# MCASP0_CFG register map
Vendor: Texas Instruments
Registers are 32-bit, read-write, reset 0x0 unless marked. A register's access mark holds for its fields unless they carry their own. Offsets are as the file gives them; [hi:lo] are bit positions; {n}, {i} and the like mark numbered series.

## MCASP0_CFG (part 2 of 3)
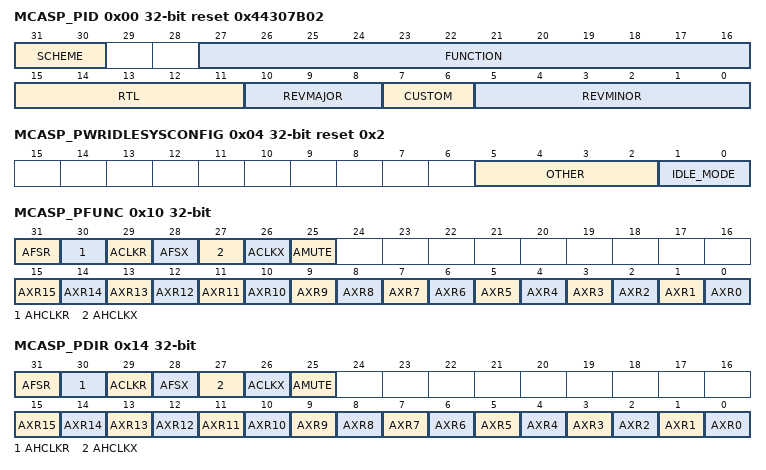
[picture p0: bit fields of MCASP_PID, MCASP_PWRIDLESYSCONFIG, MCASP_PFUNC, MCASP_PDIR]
0x00 MCASP_PID ro reset 0x44307B02
  [31:30] SCHEME — Distinguishes between old scheme and current.
  [27:16] FUNCTION — Indicates a software-compatible module family.
  [15:11] RTL — RTL version.
  [10:8] REVMAJOR — Major revision number.
  [7:6] CUSTOM — Indicates a special version for a given device.
  [5:0] REVMINOR — Minor revision number.
0x04 MCASP_PWRIDLESYSCONFIG access per field reset 0x2 — Power Idle SYSCONFIG register.
  [5:2] OTHER rw — Reserved for future programming.
  [1:0] IDLE_MODE rw — Power management Configuration of the local target state management mode. By definition, target can handle read/write transaction as long as it is out of IDLE state. 0h = Force-idle mode: local target's idle state follows (acknowledges) the system's idle requests unconditionally, i.e. regardless of the IP module's internal requirements. Backup mode, for debug only. 1h = No-idle mode: local target never enters idle state. Backup mode, for debug only. 2h = Smart-idle mode: local target's idle state eventually follows (acknowledges) the system's idle requests, depending on the IP module's internal requirements. IP module shall not generate (IRQor DMA-request-related) wakeup events. 3h = Reserved.
0x10 MCASP_PFUNC access per field
  [31] AFSR rw — Determines if AFSR pin functions as McASP or GPIO.0h = Pin functions as McASP pin. 1h = Pin functions as GPIO pin.
  [30] AHCLKR rw — Determines if AHCLKR pin functions as McASP or GPIO.0h = Pin functions as McASP pin. 1h = Pin functions as GPIO pin.
  [29] ACLKR rw — Determines if ACLKR pin functions as McASP or GPIO.0h = Pin functions as McASP pin. 1h = Pin functions as GPIO pin.
  [28] AFSX rw — Determines if AFSX pin functions as McASP or GPIO.0h = Pin functions as McASP pin. 1h = Pin functions as GPIO pin.
  [27] AHCLKX rw — Determines if AHCLKX pin functions as McASP or GPIO.0h = Pin functions as McASP pin. 1h = Pin functions as GPIO pin.
  [26] ACLKX rw — Determines if ACLKX pin functions as McASP or GPIO.0h = Pin functions as McASP pin. 1h = Pin functions as GPIO pin.
  [25] AMUTE rw — Determines if AMUTE pin functions as McASP or GPIO.0h = Pin functions as McASP pin. 1h = Pin functions as GPIO pin.
  [n] AXR{n} rw (n=0..15) — Determines if AXR{n} pin functions as McASP or GPIO.0h = Pin functions as McASP pin. 1h = Pin functions as GPIO pin.
0x14 MCASP_PDIR access per field
  [31] AFSR rw — Determines if AFSR pin functions as an input or output.0h = Pin functions as input. 1h = Pin functions as output.
  [30] AHCLKR rw — Determines if AHCLKR pin functions as an input or output.0h = Pin functions as input. 1h = Pin functions as output.
  [29] ACLKR rw — Determines if ACLKR pin functions as an input or output.0h = Pin functions as input. 1h = Pin functions as output.
  [28] AFSX rw — Determines if AFSX pin functions as an input or output.0h = Pin functions as input. 1h = Pin functions as output.
  [27] AHCLKX rw — Determines if AHCLKX pin functions as an input or output.0h = Pin functions as input. 1h = Pin functions as output.
  [26] ACLKX rw — Determines if ACLKX pin functions as an input or output.0h = Pin functions as input. 1h = Pin functions as output.
  [25] AMUTE rw — Determines if AMUTE pin functions as an input or output.0h = Pin functions as input. 1h = Pin functions as output.
  [n] AXR{n} rw (n=0..15) — Determines if AXR{n} pin functions as an input or output.0h = Pin functions as input. 1h = Pin functions as output.
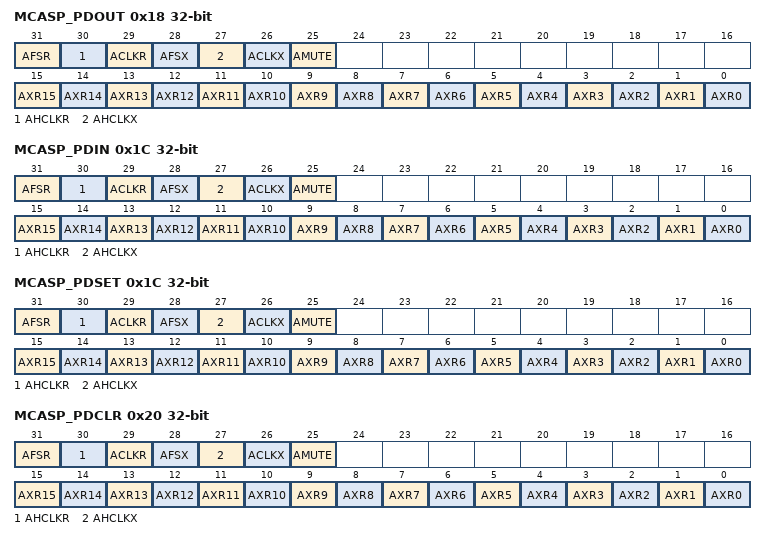
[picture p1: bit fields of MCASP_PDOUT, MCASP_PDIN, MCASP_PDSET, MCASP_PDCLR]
0x18 MCASP_PDOUT access per field
  [31] AFSR rw — Determines drive on AFSR output pin when the correspondingMCASP_PFUNC[31] and MCASP_PDIR[31] bits are set to 1. 0h = Pin drives low. 1h = Pin drives high.
  [30] AHCLKR rw — Determines drive on AHCLKR output pin when the correspondingMCASP_PFUNC[30] and MCASP_PDIR[30] bits are set to 1. 0h = Pin drives low. 1h = Pin drives high.
  [29] ACLKR rw — Determines drive on ACLKR output pin when the correspondingMCASP_PFUNC[29] and MCASP_PDIR[29] bits are set to 1. 0h = Pin drives low. 1h = Pin drives high.
  [28] AFSX rw — Determines drive on AFSX output pin when the correspondingMCASP_PFUNC[28] and MCASP_PDIR[28] bits are set to 1. 0h = Pin drives low. 1h = Pin drives high.
  [27] AHCLKX rw — Determines drive on AHCLKX output pin when the correspondingMCASP_PFUNC[27] and MCASP_PDIR[27] bits are set to 1. 0h = Pin drives low. 1h = Pin drives high.
  [26] ACLKX rw — Determines drive on ACLKX output pin when the correspondingMCASP_PFUNC[26] and MCASP_PDIR[26] bits are set to 1. 0h = Pin drives low. 1h = Pin drives high.
  [25] AMUTE rw — Determines drive on AMUTE output pin when the correspondingMCASP_PFUNC[25] and MCASP_PDIR[25] bits are set to 1. 0h = Pin drives low. 1h = Pin drives high.
  [n] AXR{n} rw (n=0..15) — Determines drive on AXR{n} output pin when the correspondingMCASP_PFUNC[{n}] and MCASP_PDIR[{n}] bits are set to 1. 0h = Pin drives low. 1h = Pin drives high.
0x1C MCASP_PDIN ro — The pin data input register (PDIN) holds the I/O pin state of each of the McASP pins. PDIN allows the actual value of the pin to be read, regardless of the state of PFUNC and PDIR.
  [31] AFSR — Logic level on AFSR pin.0h = Pin is logic low. 1h = Pin is logic high.
  [30] AHCLKR — Logic level on AHCLKR pin.0h = Pin is logic low. 1h = Pin is logic high.
  [29] ACLKR — Logic level on ACLKR pin.0h = Pin is logic low. 1h = Pin is logic high.
  [28] AFSX — Logic level on AFSX pin.0h = Pin is logic low. 1h = Pin is logic high.
  [27] AHCLKX — Logic level on AHCLKX pin.0h = Pin is logic low. 1h = Pin is logic high.
  [26] ACLKX — Logic level on ACLKX pin.0h = Pin is logic low. 1h = Pin is logic high.
  [25] AMUTE — Logic level on AMUTE pin.0h = Pin is logic low. 1h = Pin is logic high.
  [n] AXR{n} (n=0..15) — Logic level on AXR{n} pin.0h = Pin is logic low. 1h = Pin is logic high.
0x1C MCASP_PDSET access per field — The pin data set register (PDSET) is an alias of the pin data output register (PDOUT) for writes only. Writing a 1 to the PDSET bit sets the corresponding bit in PDOUT and, if PFUNC = 1 (GPIO function) and PDIR = 1 (output), drives a logic high on the pin.
  [31] AFSR wo — Allows the corresponding AFSR bit inMCASP_PDOUT to be set to a logic high without affecting other I/O pins controlled by the same port. 0h = No effect. 1h =
  [30] AHCLKR wo — Allows the corresponding AHCLKR bit inMCASP_PDOUT to be set to a logic high without affecting other I/O pins controlled by the same port. 0h = No effect. 1h =
  [29] ACLKR wo — Allows the corresponding ACLKR bit inMCASP_PDOUT to be set to a logic high without affecting other I/O pins controlled by the same port. 0h = No effect. 1h =
  [28] AFSX wo — Allows the corresponding AFSX bit inMCASP_PDOUT to be set to a logic high without affecting other I/O pins controlled by the same port. 0h = No effect. 1h =
  [27] AHCLKX wo — Allows the corresponding AHCLKX bit inMCASP_PDOUT to be set to a logic high without affecting other I/O pins controlled by the same port. 0h = No effect. 1h =
  [26] ACLKX wo — Allows the corresponding ACLKX bit inMCASP_PDOUT to be set to a logic high without affecting other I/O pins controlled by the same port. 0h = No effect. 1h =
  [25] AMUTE wo — Allows the corresponding AMUTE bit inMCASP_PDOUT to be set to a logic high without affecting other I/O pins controlled by the same port. 0h = No effect. 1h =
  [n] AXR{n} wo (n=0..15) — Allows the corresponding AXR{n} bit inMCASP_PDOUT to be set to a logic high without affecting other I/O pins controlled by the same port. 0h = No effect. 1h =
0x20 MCASP_PDCLR access per field — The pin data clear register (PDCLR) is an alias of the pin data output register (PDOUT) for writes only. Writing a 1 to the PDCLR bit clears the corresponding bit in PDOUT and, if PFUNC = 1 (GPIO function) and PDIR = 1 (output), drives a logic low on the pin.
  [31] AFSR rw — Allows the corresponding AFSR bit inMCASP_PDOUT to be cleared to a logic low without affecting other I/O pins controlled by the same port. 0h = No effect. 1h =
  [30] AHCLKR rw — Allows the corresponding AHCLKR bit inMCASP_PDOUT to be cleared to a logic low without affecting other I/O pins controlled by the same port. 0h = No effect. 1h =
  [29] ACLKR rw — Allows the corresponding ACLKR bit inMCASP_PDOUT to be cleared to a logic low without affecting other I/O pins controlled by the same port. 0h = No effect. 1h =
  [28] AFSX rw — Allows the corresponding AFSX bit inMCASP_PDOUT to be cleared to a logic low without affecting other I/O pins controlled by the same port. 0h = No effect. 1h =
  [27] AHCLKX rw — Allows the corresponding AHCLKX bit inMCASP_PDOUT to be cleared to a logic low without affecting other I/O pins controlled by the same port. 0h = No effect. 1h =
  [26] ACLKX rw — Allows the corresponding ACLKX bit inMCASP_PDOUT to be cleared to a logic low without affecting other I/O pins controlled by the same port. 0h = No effect. 1h =
  [25] AMUTE rw — Allows the corresponding AMUTE bit inMCASP_PDOUT to be cleared to a logic low without affecting other I/O pins controlled by the same port. 0h = No effect. 1h =
  [n] AXR{n} rw (n=0..15) — Allows the corresponding AXR[{n}] bit inMCASP_PDOUT to be cleared to a logic low without affecting other I/O pins controlled by the same port. 0h = No effect. 1h =
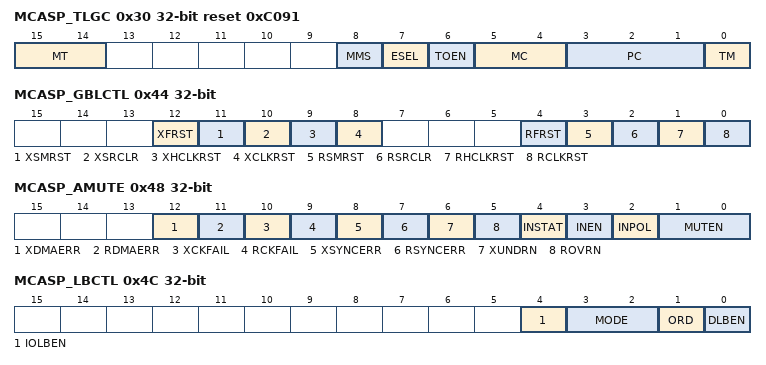
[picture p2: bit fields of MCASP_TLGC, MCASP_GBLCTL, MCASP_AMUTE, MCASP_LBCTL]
0x30 MCASP_TLGC access per field reset 0xC091 — for IODFT
  [15:14] MT rw — MISR on/off trigger command. These monitor trigger codes only are affective for the MISR signature capture when MC = 3h. MT Code effect on MISR: 0h = MISR capture start on the first active cycle decode of the IP bus activity and continues to update the signature for every active cycle. 1h = MISR capture start on the first active cycle decode of IP bus activity and continues to update the signature until the Execution Counter expires (TLEC). 2h = inactive/no effect 3h = inactive/no effect (default)
  [8] MMS rw — Chooses the source of the MISR input: 0h = output register 1h = input capture
  [7] ESEL rw — Output enable select: 0h = test mode, and the functional OEN is gated off 1h = normal functional mode
  [6] TOEN rw — Test output enable control. This signal is paired with ESEL. TOEN is never 1 when ESEL is 1. When ESEL is 0 (test mode), TOEN is: 0h = output enabled 1h = output disabled Note: In boundary scan mode this signal is not selected, and the BSR controls output enables.
  [5:4] MC rw — This defines the states of the MISR: 0h = download results 1h = hold current value 2h = load initial value (from PC bits) 3h = MISR enable to capture signature
  [3:1] PC rw — Pattern code defines the type of pattern that is selected for the artificial pattern generation logic in the IODFT. Modes: 0h = functional (default) 1h = random XOR 2h = random XNOR 3h = shift register 4h = hold current value Note: McASP does not have an input pattern generator (PG).
  [0] TM rw — At reset the value is 1 for normal functional mode. This bit is tied high, and should not be written to.
0x34 MCASP_TLMR — for IODFT
  [31:0] TLMR — This contains the result signature of a given test after the download function is executed.
0x38 MCASP_TLEC — for IODFT
  [31:0] TLEC — Contains the number of cycles during which the MISR signature will be accumulated.
0x44 MCASP_GBLCTL access per field
  [12] XFRST rw — Transmit frame sync generator reset enable bit.0h = Transmit frame sync generator is reset. 1h = Transmit frame sync generator is active. When released from reset, the transmit frame sync generator begins counting serial clocks and generating frame sync as programmed.
  [11] XSMRST rw — Transmit state machine reset enable bit.0h = Transmit state machine is held in reset. AXRn pin state: If 1h = Transmit state machine is released from reset. When released from reset, the transmit state machine immediately transfers data from XRBUF[n] to XRSR[n]. The transmit state machine sets the underrun flag (XUNDRN) in MCASP_XSTAT, if XRBUF[n] have not been preloaded with data before reset is released. The transmit state machine also immediately begins detecting frame sync and is ready to transmit. Transmit TDM time slot begins at slot 0 after reset is released.
  [10] XSRCLR rw — Transmit serializer clear enable bit. By clearing then setting this bit, the transmit buffer is flushed to an empty state [XDATA = 1]. If XSMRST = 1, XSRCLR = 1, XDATA = 1, and XBUF is not loaded with new data before the start of the next active time slot, an underrun will occur. 0h = Transmit serializers are cleared. 1h = Transmit serializers are active. When the transmit serializers are first taken out of reset (XSRCLR changes from 0 to 1), the transmit data ready bit (XDATA) in MCASP_XSTAT is set to indicate XBUF is ready to be written.
  [9] XHCLKRST rw — Transmit high-frequency clock divider reset enable bit.0h = Transmit high-frequency clock divider is held in reset and passes through its input as divide-by-1. 1h = Transmit high-frequency clock divider is running.
  [8] XCLKRST rw — Transmit clock divider reset enable bit.0h = Transmit clock divider is held in reset. When the clock divider is in reset, it passes through a divide-by-1 of its input. 1h = Transmit clock divider is running.
  [4] RFRST rw — Receive frame sync generator reset enable bit.0h = Receive frame sync generator is reset. 1h = Receive frame sync generator is active. When released from reset, the receive frame sync generator begins counting serial clocks and generating frame sync as programmed.
  [3] RSMRST rw — Receive state machine reset enable bit.0h = Receive state machine is held in reset. 1h = Receive state machine is released from reset. When released from reset, the receive state machine immediately begins detecting frame sync and is ready to receive. Receive TDM time slot begins at slot 0 after reset is released.
  [2] RSRCLR rw — Receive serializer clear enable bit. By clearing then setting this bit, the receive buffer is flushed. 0h = Receive serializers are cleared. 1h = Receive serializers are active.
  [1] RHCLKRST rw — Receive high-frequency clock divider reset enable bit.0h = Receive high-frequency clock divider is held in reset and passes through its input as divide-by-1. 1h = Receive high-frequency clock divider is running.
  [0] RCLKRST rw — Receive high-frequency clock divider reset enable bit.0h = Receive clock divider is held in reset. When the clock divider is in reset, it passes through a divide-by-1 of its input. 1h = Receive clock divider is running.
0x48 MCASP_AMUTE access per field
  [12] XDMAERR rw — If transmit DMA error [XDMAERR], driveMCASP_AMUTE active enable bit. 0h = Drive is disabled. Detection of transmit DMA error is ignored by 1h = Drive is enabled (active). Upon detection of transmit DMA error,
  [11] RDMAERR rw — If receive DMA error [RDMAERR], driveMCASP_AMUTE active enable bit. 0h = Drive is disabled. Detection of receive DMA error is ignored by 1h = Drive is enabled (active). Upon detection of receive DMA error,
  [10] XCKFAIL rw — If transmit clock failure [XCKFAIL], driveMCASP_AMUTE active enable bit. 0h = Drive is disabled. Detection of transmit clock failure is ignored by 1h = Drive is enabled (active). Upon detection of transmit clock failure,
  [9] RCKFAIL rw — If receive clock failure [RCKFAIL], driveMCASP_AMUTE active enable bit. 0h = Drive is disabled. Detection of receive clock failure is ignored by 1h = Drive is enabled (active). Upon detection of receive clock failure,
  [8] XSYNCERR rw — If unexpected transmit frame sync error [XSYNCERR], driveMCASP_AMUTE active enable bit. 0h = Drive is disabled. Detection of unexpected transmit frame sync error is ignored by 1h = Drive is enabled (active). Upon detection of unexpected transmit frame sync error,
  [7] RSYNCERR rw — If unexpected receive frame sync error [RSYNCERR], driveMCASP_AMUTE active enable bit. 0h = Drive is disabled. Detection of unexpected receive frame sync error is ignored by 1h = Drive is enabled (active). Upon detection of unexpected receive frame sync error,
  [6] XUNDRN rw — If transmit underrun error [XUNDRN], driveMCASP_AMUTE active enable bit. 0h = Drive is disabled. Detection of transmit underrun error is ignored by 1h = Drive is enabled (active). Upon detection of transmit underrun error,
  [5] ROVRN rw — If receiver overrun error [ROVRN], driveMCASP_AMUTE active enable bit. 0h = Drive is disabled. Detection of receiver overrun error is ignored by 1h = Drive is enabled (active). Upon detection of receiver overrun error,
  [4] INSTAT ro — Determines drive on AXRn pin whenMCASP_PFUNC[n] and MCASP_PDIR[n] bits are set to 1. 0h = AMUTEIN pin is inactive. 1h = AMUTEIN pin is active. Audio mute in error is detected.
  [3] INEN rw — DriveMCASP_AMUTE active when AMUTEIN error is active [INSTAT = 1]. 0h = Drive is disabled. AMUTEIN is ignored by 1h = Drive is enabled (active). INSTAT = 1 drives
  [2] INPOL rw — Audio mute in [AMUTEIN] polarity select bit.0h = Polarity is active high. A high on AMUTEIN sets INSTAT to 1. 1h = Polarity is active low. A low on AM UTEIN sets INSTAT to 1.
  [1:0] MUTEN rw — MCASP_AMUTE pin enable bit [unless overridden by GPIO registers]. 0h = 1h = 2h = 3h = Reserved
0x4C MCASP_LBCTL
  [4] IOLBEN — I/O loopback enable. Chip-level loopback; looped back through I/O buffers. 0h = I/O loopback disabled 1h = I/O loopback enabled Note: These are only valid if LBEN = 1. If LBEN = 0, neither internal nor I/O loopback will be selected.
  [3:2] MODE — Loopback generator mode bits. Applies only when loopback mode is enabled [DLBEN = 1]. 0h = Default and reserved on loopback mode (DLBEN = 1). When in non-loopback mode (DLBEN = 0), MODE should be left at default (00). When in loopback mode (DLBEN = 1), MODE = 00 is reserved and is not applicable. 1h = Transmit clock and frame sync generators used by both transmit and receive sections. When in loopback mode (DLBEN = 1), MODE must be 01. 2h = Reserved. 3h = Reserved.
  [1] ORD — Loopback order bit when loopback mode is enabled [DLBEN = 1].0h = Odd serializers N + 1 transmit to even serializers N that receive. The corresponding serializers must be programmed properly. 1h = Even serializers N transmit to odd serializers N + 1 that receive. The corresponding serializers must be programmed properly.
  [0] DLBEN — Loopback mode enable bit.0h = Loopback mode is disabled. 1h = Loopback mode is enabled.
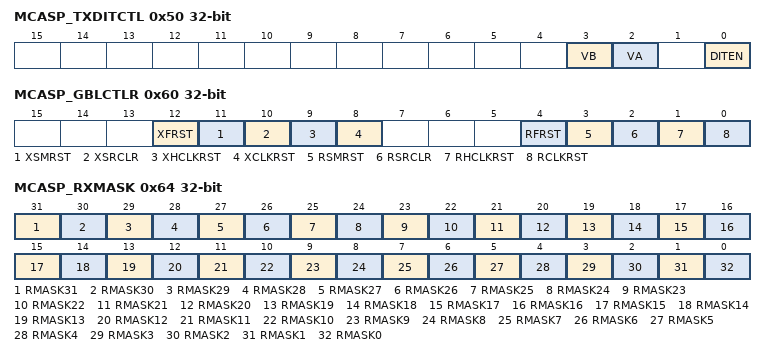
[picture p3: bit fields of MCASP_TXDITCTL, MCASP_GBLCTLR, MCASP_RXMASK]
0x50 MCASP_TXDITCTL
  [3] VB — Valid bit for odd time slots [DIT right subframe].0h = V bit is 0 during odd DIT subframes. 1h = V bit is 1 during odd DIT subframes.
  [2] VA — Valid bit for even time slots [DIT left subframe].0h = V bit is 0 during even DIT subframes. 1h = V bit is 1 during even DIT subframes.
  [0] DITEN — DIT mode enable bit. DITEN should only be changed while the XSMRST bit in MCASP_GBLCTL is in reset [and for startup, XSRCLR also in reset]. However, it is not necessary to reset the XCLKRST or XHCLKRST bits in MCASP_GBLCTL to change DITEN. 0h = DIT mode is disabled. Transmitter operates in TDM or burst mode. 1h = DIT mode is enabled. Transmitter operates in DIT encoded mode.
0x60 MCASP_GBLCTLR access per field
  [12] XFRST ro — Transmit frame sync generator reset enable bit. A read of this bit returns the XFRST bit value of MCASP_GBLCTL. Writes have no effect.
  [11] XSMRST ro — Transmit state machine reset enable bit. A read of this bit returns the XSMRST bit value of MCASP_GBLCTL. Writes have no effect.
  [10] XSRCLR ro — Transmit serializer clear enable bit. A read of this bit returns the XSRCLR bit value of MCASP_GBLCTL. Writes have no effect.
  [9] XHCLKRST ro — Transmit high-frequency clock divider reset enable bit. A read of this bit returns the XHCLKRST bit value of MCASP_GBLCTL. Writes have no effect.
  [8] XCLKRST ro — Transmit clock divider reset enable bit. A read of this bit returns the XCLKRST bit value of MCASP_GBLCTL. Writes have no effect.
  [4] RFRST rw — Receive frame sync generator reset enable bit. A write to this bit affects the RFRST bit of MCASP_GBLCTL. 0h = Receive frame sync generator is reset. 1h = Receive frame sync generator is active.
  [3] RSMRST rw — Receive state machine reset enable bit. A write to this bit affects the RSMRST bit of MCASP_GBLCTL. 0h = Receive state machine is held in reset. 1h = Receive state machine is released from reset.
  [2] RSRCLR rw — Receive serializer clear enable bit. A write to this bit affects the RSRCLR bit of MCASP_GBLCTL. 0h = Receive serializers are cleared. 1h = Receive serializers are active.
  [1] RHCLKRST rw — Receive high-frequency clock divider reset enable bit. A write to this bit affects the RHCLKRST bit of MCASP_GBLCTL. 0h = Receive high-frequency clock divider is held in reset and passes through its input as divide-by-1. 1h = Receive high-frequency clock divider is running.
  [0] RCLKRST rw — Receive clock divider reset enable bit. A write to this bit affects the RCLKRST bit of MCASP_GBLCTL. 0h = Receive clock divider is held in reset. 1h = Receive clock divider is running.
0x64 MCASP_RXMASK
  [31] RMASK31 — Receive data mask 31 enable bit.0h = Corresponding bit of receive data (after passing through reverse and rotate units) is masked out and then padded with the selected bit pad value (RPAD and RPBIT bits in MCASP_RFMT). 1h = Corresponding bit of receive data (after passing through reverse and rotate units) is returned to CPU or DMA.
  [30] RMASK30 — Receive data mask 30 enable bit.0h = Corresponding bit of receive data (after passing through reverse and rotate units) is masked out and then padded with the selected bit pad value (RPAD and RPBIT bits in MCASP_RFMT). 1h = Corresponding bit of receive data (after passing through reverse and rotate units) is returned to CPU or DMA.
  [29] RMASK29 — Receive data mask 29 enable bit.0h = Corresponding bit of receive data (after passing through reverse and rotate units) is masked out and then padded with the selected bit pad value (RPAD and RPBIT bits in MCASP_RFMT). 1h = Corresponding bit of receive data (after passing through reverse and rotate units) is returned to CPU or DMA.
  [28] RMASK28 — Receive data mask 28 enable bit.0h = Corresponding bit of receive data (after passing through reverse and rotate units) is masked out and then padded with the selected bit pad value (RPAD and RPBIT bits in MCASP_RFMT). 1h = Corresponding bit of receive data (after passing through reverse and rotate units) is returned to CPU or DMA.
  [27] RMASK27 — Receive data mask 27 enable bit.0h = Corresponding bit of receive data (after passing through reverse and rotate units) is masked out and then padded with the selected bit pad value (RPAD and RPBIT bits in MCASP_RFMT). 1h = Corresponding bit of receive data (after passing through reverse and rotate units) is returned to CPU or DMA.
  [26] RMASK26 — Receive data mask 26 enable bit.0h = Corresponding bit of receive data (after passing through reverse and rotate units) is masked out and then padded with the selected bit pad value (RPAD and RPBIT bits in MCASP_RFMT). 1h = Corresponding bit of receive data (after passing through reverse and rotate units) is returned to CPU or DMA.
  [25] RMASK25 — Receive data mask 25 enable bit.0h = Corresponding bit of receive data (after passing through reverse and rotate units) is masked out and then padded with the selected bit pad value (RPAD and RPBIT bits in MCASP_RFMT). 1h = Corresponding bit of receive data (after passing through reverse and rotate units) is returned to CPU or DMA.
  [24] RMASK24 — Receive data mask 24 enable bit.0h = Corresponding bit of receive data (after passing through reverse and rotate units) is masked out and then padded with the selected bit pad value (RPAD and RPBIT bits in MCASP_RFMT). 1h = Corresponding bit of receive data (after passing through reverse and rotate units) is returned to CPU or DMA.
  [23] RMASK23 — Receive data mask 23 enable bit.0h = Corresponding bit of receive data (after passing through reverse and rotate units) is masked out and then padded with the selected bit pad value (RPAD and RPBIT bits in MCASP_RFMT). 1h = Corresponding bit of receive data (after passing through reverse and rotate units) is returned to CPU or DMA.
  [22] RMASK22 — Receive data mask 22 enable bit.0h = Corresponding bit of receive data (after passing through reverse and rotate units) is masked out and then padded with the selected bit pad value (RPAD and RPBIT bits in MCASP_RFMT). 1h = Corresponding bit of receive data (after passing through reverse and rotate units) is returned to CPU or DMA.
  [21] RMASK21 — Receive data mask 21 enable bit.0h = Corresponding bit of receive data (after passing through reverse and rotate units) is masked out and then padded with the selected bit pad value (RPAD and RPBIT bits in MCASP_RFMT). 1h = Corresponding bit of receive data (after passing through reverse and rotate units) is returned to CPU or DMA.
  [20] RMASK20 — Receive data mask 20 enable bit.0h = Corresponding bit of receive data (after passing through reverse and rotate units) is masked out and then padded with the selected bit pad value (RPAD and RPBIT bits in MCASP_RFMT). 1h = Corresponding bit of receive data (after passing through reverse and rotate units) is returned to CPU or DMA.
  [19] RMASK19 — Receive data mask 19 enable bit.0h = Corresponding bit of receive data (after passing through reverse and rotate units) is masked out and then padded with the selected bit pad value (RPAD and RPBIT bits in MCASP_RFMT). 1h = Corresponding bit of receive data (after passing through reverse and rotate units) is returned to CPU or DMA.
  [18] RMASK18 — Receive data mask 18 enable bit.0h = Corresponding bit of receive data (after passing through reverse and rotate units) is masked out and then padded with the selected bit pad value (RPAD and RPBIT bits in MCASP_RFMT). 1h = Corresponding bit of receive data (after passing through reverse and rotate units) is returned to CPU or DMA.
  [17] RMASK17 — Receive data mask 17 enable bit.0h = Corresponding bit of receive data (after passing through reverse and rotate units) is masked out and then padded with the selected bit pad value (RPAD and RPBIT bits in MCASP_RFMT). 1h = Corresponding bit of receive data (after passing through reverse and rotate units) is returned to CPU or DMA.
  [16] RMASK16 — Receive data mask 16 enable bit.0h = Corresponding bit of receive data (after passing through reverse and rotate units) is masked out and then padded with the selected bit pad value (RPAD and RPBIT bits in MCASP_RFMT). 1h = Corresponding bit of receive data (after passing through reverse and rotate units) is returned to CPU or DMA.
  [15] RMASK15 — Receive data mask 15 enable bit.0h = Corresponding bit of receive data (after passing through reverse and rotate units) is masked out and then padded with the selected bit pad value (RPAD and RPBIT bits in MCASP_RFMT). 1h = Corresponding bit of receive data (after passing through reverse and rotate units) is returned to CPU or DMA.
  [14] RMASK14 — Receive data mask 14 enable bit.0h = Corresponding bit of receive data (after passing through reverse and rotate units) is masked out and then padded with the selected bit pad value (RPAD and RPBIT bits in MCASP_RFMT). 1h = Corresponding bit of receive data (after passing through reverse and rotate units) is returned to CPU or DMA.
  [13] RMASK13 — Receive data mask 13 enable bit.0h = Corresponding bit of receive data (after passing through reverse and rotate units) is masked out and then padded with the selected bit pad value (RPAD and RPBIT bits in MCASP_RFMT). 1h = Corresponding bit of receive data (after passing through reverse and rotate units) is returned to CPU or DMA.
  [12] RMASK12 — Receive data mask 12 enable bit.0h = Corresponding bit of receive data (after passing through reverse and rotate units) is masked out and then padded with the selected bit pad value (RPAD and RPBIT bits in MCASP_RFMT). 1h = Corresponding bit of receive data (after passing through reverse and rotate units) is returned to CPU or DMA.
  [11] RMASK11 — Receive data mask 11 enable bit.0h = Corresponding bit of receive data (after passing through reverse and rotate units) is masked out and then padded with the selected bit pad value (RPAD and RPBIT bits in MCASP_RFMT). 1h = Corresponding bit of receive data (after passing through reverse and rotate units) is returned to CPU or DMA.
  [10] RMASK10 — Receive data mask 10 enable bit.0h = Corresponding bit of receive data (after passing through reverse and rotate units) is masked out and then padded with the selected bit pad value (RPAD and RPBIT bits in MCASP_RFMT). 1h = Corresponding bit of receive data (after passing through reverse and rotate units) is returned to CPU or DMA.
  [9] RMASK9 — Receive data mask 9 enable bit.0h = Corresponding bit of receive data (after passing through reverse and rotate units) is masked out and then padded with the selected bit pad value (RPAD and RPBIT bits in MCASP_RFMT). 1h = Corresponding bit of receive data (after passing through reverse and rotate units) is returned to CPU or DMA.
  [8] RMASK8 — Receive data mask 8 enable bit.0h = Corresponding bit of receive data (after passing through reverse and rotate units) is masked out and then padded with the selected bit pad value (RPAD and RPBIT bits in MCASP_RFMT). 1h = Corresponding bit of receive data (after passing through reverse and rotate units) is returned to CPU or DMA.
  [7] RMASK7 — Receive data mask 7 enable bit.0h = Corresponding bit of receive data (after passing through reverse and rotate units) is masked out and then padded with the selected bit pad value (RPAD and RPBIT bits in MCASP_RFMT). 1h = Corresponding bit of receive data (after passing through reverse and rotate units) is returned to CPU or DMA.
  [6] RMASK6 — Receive data mask 6 enable bit.0h = Corresponding bit of receive data (after passing through reverse and rotate units) is masked out and then padded with the selected bit pad value (RPAD and RPBIT bits in MCASP_RFMT). 1h = Corresponding bit of receive data (after passing through reverse and rotate units) is returned to CPU or DMA.
  [5] RMASK5 — Receive data mask 5 enable bit.0h = Corresponding bit of receive data (after passing through reverse and rotate units) is masked out and then padded with the selected bit pad value (RPAD and RPBIT bits in MCASP_RFMT). 1h = Corresponding bit of receive data (after passing through reverse and rotate units) is returned to CPU or DMA.
  [4] RMASK4 — Receive data mask 4 enable bit.0h = Corresponding bit of receive data (after passing through reverse and rotate units) is masked out and then padded with the selected bit pad value (RPAD and RPBIT bits in MCASP_RFMT). 1h = Corresponding bit of receive data (after passing through reverse and rotate units) is returned to CPU or DMA.
  [3] RMASK3 — Receive data mask 3 enable bit.0h = Corresponding bit of receive data (after passing through reverse and rotate units) is masked out and then padded with the selected bit pad value (RPAD and RPBIT bits in MCASP_RFMT). 1h = Corresponding bit of receive data (after passing through reverse and rotate units) is returned to CPU or DMA.
  [2] RMASK2 — Receive data mask 2 enable bit.0h = Corresponding bit of receive data (after passing through reverse and rotate units) is masked out and then padded with the selected bit pad value (RPAD and RPBIT bits in MCASP_RFMT). 1h = Corresponding bit of receive data (after passing through reverse and rotate units) is returned to CPU or DMA.
  [1] RMASK1 — Receive data mask 1 enable bit.0h = Corresponding bit of receive data (after passing through reverse and rotate units) is masked out and then padded with the selected bit pad value (RPAD and RPBIT bits in MCASP_RFMT). 1h = Corresponding bit of receive data (after passing through reverse and rotate units) is returned to CPU or DMA.
  [0] RMASK0 — Receive data mask 0 enable bit.0h = Corresponding bit of receive data (after passing through reverse and rotate units) is masked out and then padded with the selected bit pad value (RPAD and RPBIT bits in MCASP_RFMT). 1h = Corresponding bit of receive data (after passing through reverse and rotate units) is returned to CPU or DMA.
